AUTOSAR XML (schema 4-2-2)
package /Components
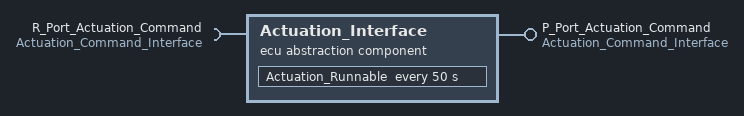
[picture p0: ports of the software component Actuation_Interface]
  ecu abstraction sw component type Actuation_Interface
    provide port P_Port_Actuation_Command: provided-interface=Actuation_Command_Interface
    require port R_Port_Actuation_Command: required-interface=Actuation_Command_Interface
    behavior Actuation_Interface_Internal_Behavior
      data send completed event Actuation_Sent: start-on-event=Actuation_Runnable, event-source=Actuation_Command_Input
      timing event Actuation_Tick: start-on-event=Actuation_Runnable, period=50
      runnable Actuation_Runnable: symbol=Actuation_Interface_Symbol
        data-receive-point-by-arguments:
          access Actuation_Command_Input: accessed-variable=R_Port_Actuation_Command.Actuation_Command
        data-send-points:
          access Actuation_Command_Output: accessed-variable=P_Port_Actuation_Command.Actuation_Command
